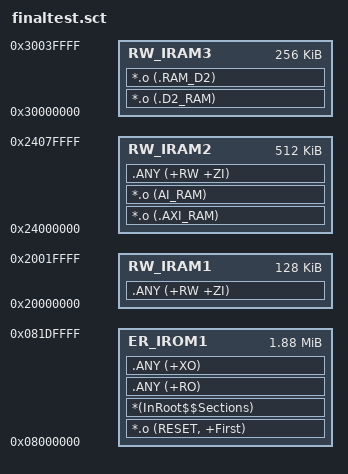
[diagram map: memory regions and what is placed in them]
LR_IROM1 0x08000000 0x00200000  {    ; 2MB total flash
  ER_IROM1 0x08000000 0x001E0000  {  ; 1.875MB code: Bank1 + Bank2 S0~6
   *.o (RESET, +First)               ; Bank2 Sector7 (0x081E0000,128KB) reserved for flash_storage
   *(InRoot$$Sections)
   .ANY (+RO)
   .ANY (+XO)
  }
  RW_IRAM1 0x20000000 0x00020000  {  ; DTCM 128KB: stack, small vars, RTOS
   .ANY (+RW +ZI)
  }
  RW_IRAM2 0x24000000 0x00080000  {  ; AXI SRAM 512KB: AI, RGB_DATA
   *.o (.AXI_RAM)
   *.o (AI_RAM)
   .ANY (+RW +ZI)
  }
  RW_IRAM3 0x30000000 0x00040000  {  ; SRAM1+2 256KB: DMA buf, LCD buf
   *.o (.D2_RAM)
   *.o (.RAM_D2)
  }
}
